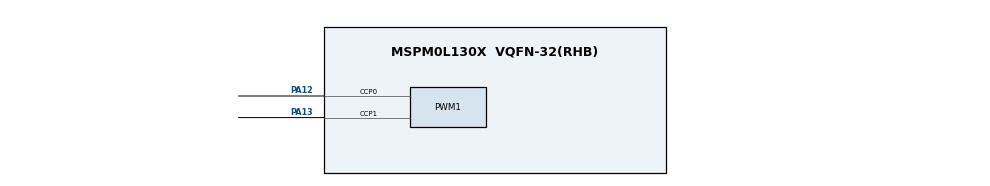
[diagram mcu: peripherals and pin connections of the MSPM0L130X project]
// @cliArgs --device "MSPM0L130X" --package "VQFN-32(RHB)" --part "Default"
// @cliArgs --board /ti/boards/LP_MSPM0L1306 --rtos nortos

/**
 * Import the modules used in this configuration.
 */
const PWM    = scripting.addModule("/ti/driverlib/PWM", {}, false);
const PWM1   = PWM.addInstance();
const SYSCTL = scripting.addModule("/ti/driverlib/SYSCTL");

/**
 * Write custom configuration values to the imported modules.
 */
PWM1.$name                   = "PWM_0";
PWM1.clockSource             = "LFCLK";
PWM1.clockPrescale           = 3;
PWM1.timerCount              = 4000;
PWM1.pwmMode                 = "CENTER_ALIGN";
PWM1.PWM_CHANNEL_0.$name     = "ti_driverlib_pwm_PWMTimerCC0";
PWM1.PWM_CHANNEL_0.dutyCycle = 75;
PWM1.PWM_CHANNEL_0.ccValue   = 500;
PWM1.PWM_CHANNEL_1.$name     = "ti_driverlib_pwm_PWMTimerCC1";
PWM1.PWM_CHANNEL_1.dutyCycle = 50;
PWM1.PWM_CHANNEL_1.ccValue   = 1000;
PWM1.peripheral.$assign =      "TIMG0";
PWM1.peripheral.ccp0Pin.$assign = "PA12";
PWM1.peripheral.ccp1Pin.$assign = "PA13";

const Board = scripting.addModule("/ti/driverlib/Board", {}, false);
Board.configureUnused = true;

SYSCTL.powerPolicy = "STOP2";
SYSCTL.clockTreeEn = true;
